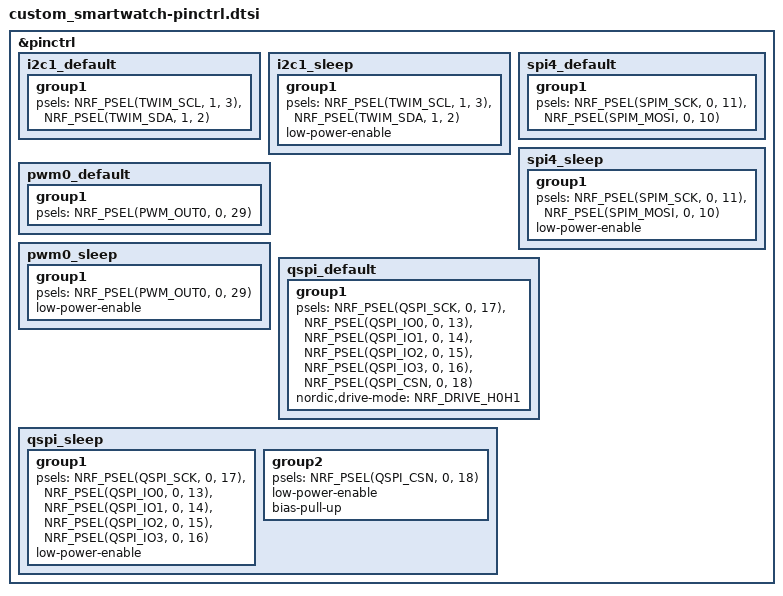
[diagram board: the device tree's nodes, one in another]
/*
 * SPDX-License-Identifier: Apache-2.0
 */

&pinctrl {
	i2c1_default: i2c1_default {
		group1 {
			psels = <NRF_PSEL(TWIM_SCL, 1, 3)>,
				<NRF_PSEL(TWIM_SDA, 1, 2)>;
		};
	};

	i2c1_sleep: i2c1_sleep {
		group1 {
			psels = <NRF_PSEL(TWIM_SCL, 1, 3)>,
				<NRF_PSEL(TWIM_SDA, 1, 2)>;
			low-power-enable;
		};
	};

	spi4_default: spi4_default {
		group1 {
			psels = <NRF_PSEL(SPIM_SCK, 0, 11)>,
				<NRF_PSEL(SPIM_MOSI, 0, 10)>;
		};
	};

	spi4_sleep: spi4_sleep {
		group1 {
			psels = <NRF_PSEL(SPIM_SCK, 0, 11)>,
				<NRF_PSEL(SPIM_MOSI, 0, 10)>;
			low-power-enable;
		};
	};

	pwm0_default: pwm0_default {
		group1 {
			psels = <NRF_PSEL(PWM_OUT0, 0, 29)>;
		};
	};

	pwm0_sleep: pwm0_sleep {
		group1 {
			psels = <NRF_PSEL(PWM_OUT0, 0, 29)>;
			low-power-enable;
		};
	};

	qspi_default: qspi_default {
		group1 {
			psels = <NRF_PSEL(QSPI_SCK, 0, 17)>,
				<NRF_PSEL(QSPI_IO0, 0, 13)>,
				<NRF_PSEL(QSPI_IO1, 0, 14)>,
				<NRF_PSEL(QSPI_IO2, 0, 15)>,
				<NRF_PSEL(QSPI_IO3, 0, 16)>,
				<NRF_PSEL(QSPI_CSN, 0, 18)>;
			nordic,drive-mode = <NRF_DRIVE_H0H1>;
		};
	};

	qspi_sleep: qspi_sleep {
		group1 {
			psels = <NRF_PSEL(QSPI_SCK, 0, 17)>,
				<NRF_PSEL(QSPI_IO0, 0, 13)>,
				<NRF_PSEL(QSPI_IO1, 0, 14)>,
				<NRF_PSEL(QSPI_IO2, 0, 15)>,
				<NRF_PSEL(QSPI_IO3, 0, 16)>;
			low-power-enable;
		};

		group2 {
			psels = <NRF_PSEL(QSPI_CSN, 0, 18)>;
			low-power-enable;
			bias-pull-up;
		};
	};
};
